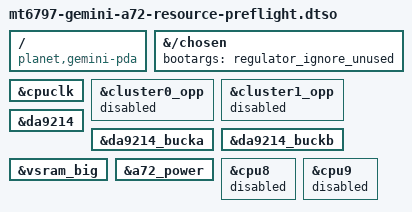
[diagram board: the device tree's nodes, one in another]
// SPDX-License-Identifier: (GPL-2.0-only OR MIT)
/*
 * Planet Computers Gemini PDA Cortex-A72 resource preflight.
 *
 * This is the provider-only half of a volatile CPU8 admission candidate.  It
 * makes only the resources needed to read and transactionally prepare the
 * dormant MP2 path available.  CPU8 and CPU9 remain closed here, no OPP is
 * exposed, and the custom CPU operation rejects CPU_ON without publishing an
 * admission owner.  Userspace must pass the read-only helper before booting a
 * separate CPU8 candidate.
 *
 * regulator_ignore_unused is part of the safety contract: it prevents the
 * regulator core from changing either otherwise-unused output after the
 * read-only identity and state capture.  DA9214 needs both physical children
 * present and available; a partial child description is not a valid provider
 * graph for this two-output device.
 */

/dts-v1/;
/plugin/;

/ {
	compatible = "planet,gemini-pda", "mediatek,mt6797";
};

&{/chosen} {
	bootargs = "regulator_ignore_unused";
};

&cpuclk {
	status = "okay";
};

&cluster0_opp {
	status = "disabled";
};

&cluster1_opp {
	status = "disabled";
};

&da9214 {
	status = "okay";
};

&da9214_bucka {
	status = "okay";
};

&da9214_buckb {
	status = "okay";
};

&vsram_big {
	status = "okay";
};

&a72_power {
	status = "okay";
};

&cpu8 {
	status = "disabled";
};

&cpu9 {
	status = "disabled";
};
